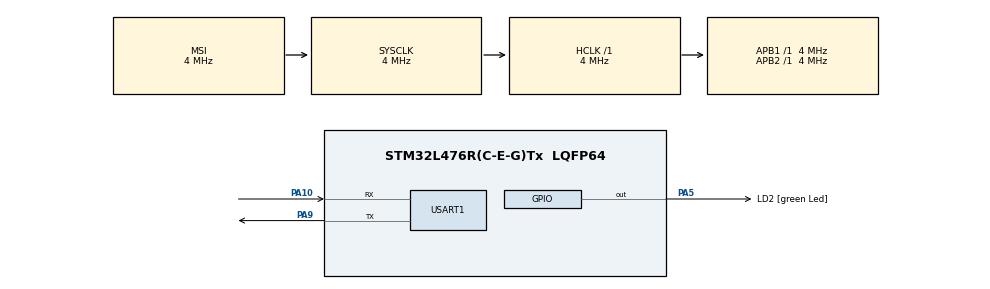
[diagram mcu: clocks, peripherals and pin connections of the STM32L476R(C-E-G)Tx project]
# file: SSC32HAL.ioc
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Mcu.Family=STM32L4
Mcu.Name=STM32L476R(C-E-G)Tx
Mcu.Package=LQFP64
NVIC.PriorityGroup=NVIC_PRIORITYGROUP_4
PA10.Mode=Asynchronous
PA10.Signal=USART1_RX
PA5.GPIO_Label=LD2 [green Led]
PA5.GPIO_ModeDefaultOutputPP=GPIO_MODE_OUTPUT_PP
PA5.GPIO_PuPd=GPIO_NOPULL
PA5.GPIO_Speed=GPIO_SPEED_FREQ_LOW
PA5.Signal=GPIO_Output
PA9.Mode=Asynchronous
PA9.Signal=USART1_TX
ProjectManager.HeapSize=0x200
ProjectManager.StackSize=0x400
ProjectManager.TargetToolchain=MDK-ARM V5.27
RCC.ADCFreq_Value=64000000
RCC.AHBFreq_Value=4000000
RCC.APB1Freq_Value=4000000
RCC.APB1TimFreq_Value=4000000
RCC.APB2Freq_Value=4000000
RCC.APB2TimFreq_Value=4000000
RCC.CortexFreq_Value=4000000
RCC.HCLKFreq_Value=4000000
RCC.HSE_VALUE=8000000
RCC.HSI_VALUE=16000000
RCC.LSE_VALUE=32768
RCC.MSI_VALUE=4000000
RCC.PLLN=10
RCC.PLLSourceVirtual=RCC_PLLSOURCE_HSI
RCC.PREFETCH_ENABLE=1
RCC.SYSCLKFreq_VALUE=4000000
RCC.USBFreq_Value=64000000
RCC.VCOOutputFreq_Value=160000000
USART1.VirtualMode-Asynchronous=VM_ASYNC
board=NUCLEO-L476RG

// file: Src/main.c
/* USER CODE BEGIN Header */
/**
  ******************************************************************************
  * @file           : main.c
  * @brief          : Main program body
  ******************************************************************************
  * @attention
  *
  * <h2><center>&copy; Copyright (c) 2021 STMicroelectronics.
  * All rights reserved.</center></h2>
  *
  * This software component is licensed by ST under BSD 3-Clause license,
  * the "License"; You may not use this file except in compliance with the
  * License. You may obtain a copy of the License at:
  *                        opensource.org/licenses/BSD-3-Clause
  *
  ******************************************************************************
  */
/* USER CODE END Header */

#include "main.h"

UART_HandleTypeDef huart1;

void SystemClock_Config(void);
static void MX_GPIO_Init(void);
static void MX_USART1_UART_Init(void);

int main(void)
{
  /* USER CODE BEGIN 1 */
    char Control[]="#0P850#1P500#2P1500#3P1300#4P1230#5P1500#0P850S500T1000\r\n";
	char Central[]="#0P1500#1P1500#2P1500#3P1500#4P1500#5P1500S500T1000\r\n";
  /* USER CODE END 1 */

  /* MCU Configuration--------------------------------------------------------*/

  /* Reset of all peripherals, Initializes the Flash interface and the Systick. */
  HAL_Init();

  /* Configure the system clock */
  SystemClock_Config();

  /* Initialize all configured peripherals */
  MX_GPIO_Init();
  MX_USART1_UART_Init();
  /* USER CODE BEGIN 2 */
  HAL_UART_Transmit(&huart1,(uint8_t *)Central,53,10);
  HAL_Delay(2000);
  HAL_UART_Transmit(&huart1,(uint8_t *)Control,57,10);

  /* USER CODE END 2 */

  /* Infinite loop */
  while (1)
  {

  }
}

void SystemClock_Config(void)
{
  RCC_OscInitTypeDef RCC_OscInitStruct = {0};
  RCC_ClkInitTypeDef RCC_ClkInitStruct = {0};
  RCC_PeriphCLKInitTypeDef PeriphClkInit = {0};

  /** Initializes the CPU, AHB and APB busses clocks
  */
  RCC_OscInitStruct.OscillatorType = RCC_OSCILLATORTYPE_MSI;
  RCC_OscInitStruct.MSIState = RCC_MSI_ON;
  RCC_OscInitStruct.MSICalibrationValue = 0;
  RCC_OscInitStruct.MSIClockRange = RCC_MSIRANGE_6;
  RCC_OscInitStruct.PLL.PLLState = RCC_PLL_NONE;
  if (HAL_RCC_OscConfig(&RCC_OscInitStruct) != HAL_OK)
  {
    Error_Handler();
  }
  /** Initializes the CPU, AHB and APB busses clocks
  */
  RCC_ClkInitStruct.ClockType = RCC_CLOCKTYPE_HCLK|RCC_CLOCKTYPE_SYSCLK
                              |RCC_CLOCKTYPE_PCLK1|RCC_CLOCKTYPE_PCLK2;
  RCC_ClkInitStruct.SYSCLKSource = RCC_SYSCLKSOURCE_MSI;
  RCC_ClkInitStruct.AHBCLKDivider = RCC_SYSCLK_DIV1;
  RCC_ClkInitStruct.APB1CLKDivider = RCC_HCLK_DIV1;
  RCC_ClkInitStruct.APB2CLKDivider = RCC_HCLK_DIV1;

  if (HAL_RCC_ClockConfig(&RCC_ClkInitStruct, FLASH_LATENCY_0) != HAL_OK)
  {
    Error_Handler();
  }
  PeriphClkInit.PeriphClockSelection = RCC_PERIPHCLK_USART1;
  PeriphClkInit.Usart1ClockSelection = RCC_USART1CLKSOURCE_PCLK2;
  if (HAL_RCCEx_PeriphCLKConfig(&PeriphClkInit) != HAL_OK)
  {
    Error_Handler();
  }
  /** Configure the main internal regulator output voltage
  */
  if (HAL_PWREx_ControlVoltageScaling(PWR_REGULATOR_VOLTAGE_SCALE1) != HAL_OK)
  {
    Error_Handler();
  }
}

static void MX_USART1_UART_Init(void)
{

  huart1.Instance = USART1;
  huart1.Init.BaudRate = 115200;
  huart1.Init.WordLength = UART_WORDLENGTH_8B;
  huart1.Init.StopBits = UART_STOPBITS_1;
  huart1.Init.Parity = UART_PARITY_NONE;
  huart1.Init.Mode = UART_MODE_TX_RX;
  huart1.Init.HwFlowCtl = UART_HWCONTROL_NONE;
  huart1.Init.OverSampling = UART_OVERSAMPLING_16;
  huart1.Init.OneBitSampling = UART_ONE_BIT_SAMPLE_DISABLE;
  huart1.AdvancedInit.AdvFeatureInit = UART_ADVFEATURE_NO_INIT;
  if (HAL_UART_Init(&huart1) != HAL_OK)
  {
    Error_Handler();
  }

}

static void MX_GPIO_Init(void)
{
  GPIO_InitTypeDef GPIO_InitStruct = {0};

  /* GPIO Ports Clock Enable */
  __HAL_RCC_GPIOA_CLK_ENABLE();

  /*Configure GPIO pin Output Level */
  HAL_GPIO_WritePin(LD2_GPIO_Port, LD2_Pin, GPIO_PIN_RESET);

  /*Configure GPIO pin : LD2_Pin */
  GPIO_InitStruct.Pin = LD2_Pin;
  GPIO_InitStruct.Mode = GPIO_MODE_OUTPUT_PP;
  GPIO_InitStruct.Pull = GPIO_NOPULL;
  GPIO_InitStruct.Speed = GPIO_SPEED_FREQ_LOW;
  HAL_GPIO_Init(LD2_GPIO_Port, &GPIO_InitStruct);

}

void Error_Handler(void)
{
}

/************************ (C) COPYRIGHT STMicroelectronics *****END OF FILE****/
